# SYSCTRL register map
Registers are 32-bit, access not given, no defined reset value unless marked. A register's access mark holds for its fields unless they carry their own. Addresses are absolute; registers are grouped by the start of their names; [hi:lo] are bit positions; {n}, {i} and the like mark numbered series; 'fields as' and 'values as' point back to an identical list.

## PWRCTRL
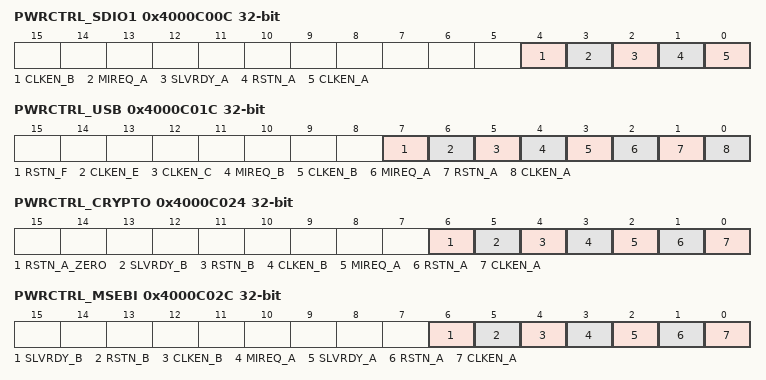
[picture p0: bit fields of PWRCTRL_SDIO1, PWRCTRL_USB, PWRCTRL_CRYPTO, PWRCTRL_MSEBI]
0x4000C00C PWRCTRL_SDIO1
  [4] CLKEN_B, [3] MIREQ_A, [2] SLVRDY_A, [1] RSTN_A, [0] CLKEN_A
0x4000C01C PWRCTRL_USB
  [7] RSTN_F, [6] CLKEN_E, [5] CLKEN_C, [4] MIREQ_B, [3] CLKEN_B, [2] MIREQ_A, [1] RSTN_A, [0] CLKEN_A
0x4000C024 PWRCTRL_CRYPTO
  [6] RSTN_A_ZERO, [5] SLVRDY_B, [4] RSTN_B, [3] CLKEN_B, [2] MIREQ_A, [1] RSTN_A, [0] CLKEN_A
0x4000C02C PWRCTRL_MSEBI
  [6] SLVRDY_B, [5] RSTN_B, [4] CLKEN_B, [3] MIREQ_A, [2] SLVRDY_A, [1] RSTN_A, [0] CLKEN_A
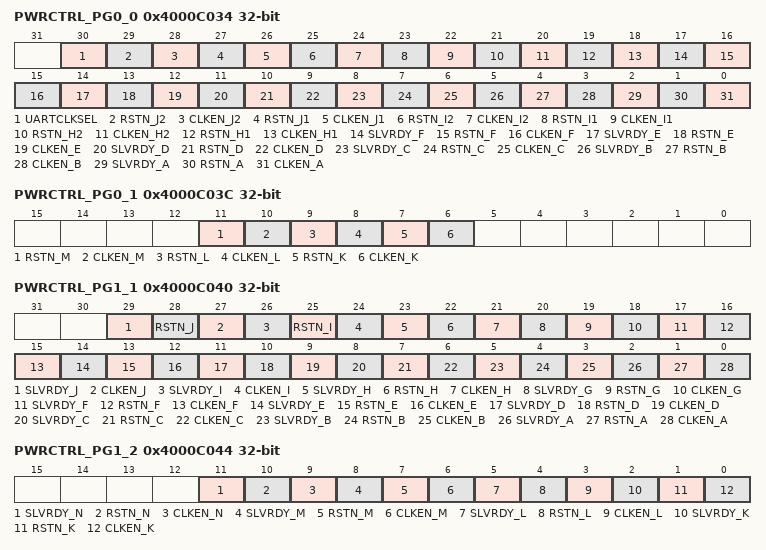
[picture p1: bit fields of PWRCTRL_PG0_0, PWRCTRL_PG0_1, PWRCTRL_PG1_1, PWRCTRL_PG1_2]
0x4000C034 PWRCTRL_PG0_0
  [30] UARTCLKSEL, [29] RSTN_J2, [28] CLKEN_J2, [27] RSTN_J1, [26] CLKEN_J1, [25] RSTN_I2, [24] CLKEN_I2, [23] RSTN_I1, [22] CLKEN_I1, [21] RSTN_H2, [20] CLKEN_H2, [19] RSTN_H1, [18] CLKEN_H1, [17] SLVRDY_F, [16] RSTN_F, [15] CLKEN_F, [14] SLVRDY_E, [13] RSTN_E, [12] CLKEN_E, [11] SLVRDY_D, [10] RSTN_D, [9] CLKEN_D, [8] SLVRDY_C, [7] RSTN_C, [6] CLKEN_C, [5] SLVRDY_B, [4] RSTN_B, [3] CLKEN_B, [2] SLVRDY_A, [1] RSTN_A, [0] CLKEN_A
0x4000C03C PWRCTRL_PG0_1
  [11] RSTN_M, [10] CLKEN_M, [9] RSTN_L, [8] CLKEN_L, [7] RSTN_K, [6] CLKEN_K
0x4000C040 PWRCTRL_PG1_1
  [29] SLVRDY_J, [28] RSTN_J, [27] CLKEN_J, [26] SLVRDY_I, [25] RSTN_I, [24] CLKEN_I, [23] SLVRDY_H, [22] RSTN_H, [21] CLKEN_H, [20] SLVRDY_G, [19] RSTN_G, [18] CLKEN_G, [17] SLVRDY_F, [16] RSTN_F, [15] CLKEN_F, [14] SLVRDY_E, [13] RSTN_E, [12] CLKEN_E, [11] SLVRDY_D, [10] RSTN_D, [9] CLKEN_D, [8] SLVRDY_C, [7] RSTN_C, [6] CLKEN_C, [5] SLVRDY_B, [4] RSTN_B, [3] CLKEN_B, [2] SLVRDY_A, [1] RSTN_A, [0] CLKEN_A
0x4000C044 PWRCTRL_PG1_2
  [11] SLVRDY_N, [10] RSTN_N, [9] CLKEN_N, [8] SLVRDY_M, [7] RSTN_M, [6] CLKEN_M, [5] SLVRDY_L, [4] RSTN_L, [3] CLKEN_L, [2] SLVRDY_K, [1] RSTN_K, [0] CLKEN_K
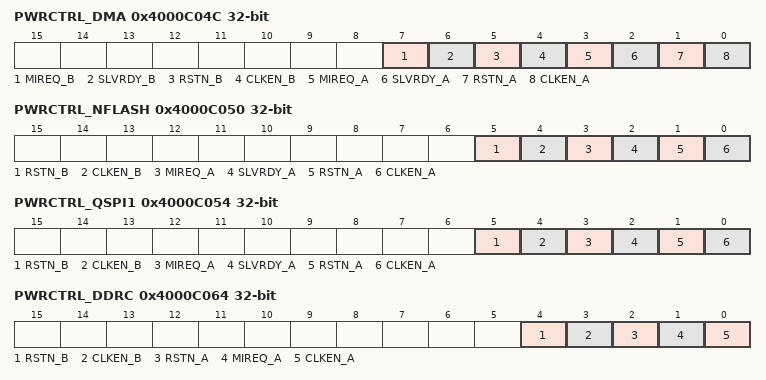
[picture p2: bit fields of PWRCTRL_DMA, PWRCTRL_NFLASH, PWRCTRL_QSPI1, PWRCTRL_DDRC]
0x4000C04C PWRCTRL_DMA
  [7] MIREQ_B, [6] SLVRDY_B, [5] RSTN_B, [4] CLKEN_B, [3] MIREQ_A, [2] SLVRDY_A, [1] RSTN_A, [0] CLKEN_A
0x4000C050 PWRCTRL_NFLASH
  [5] RSTN_B, [4] CLKEN_B, [3] MIREQ_A, [2] SLVRDY_A, [1] RSTN_A, [0] CLKEN_A
0x4000C054 PWRCTRL_QSPI1
  fields as PWRCTRL_NFLASH
0x4000C064 PWRCTRL_DDRC
  [4] RSTN_B, [3] CLKEN_B, [2] RSTN_A, [1] MIREQ_A, [0] CLKEN_A
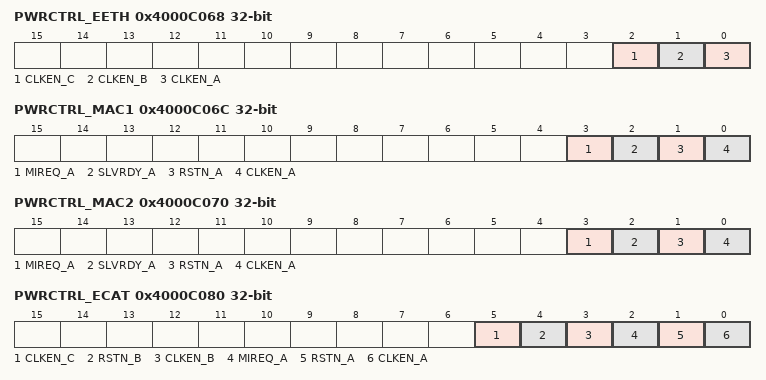
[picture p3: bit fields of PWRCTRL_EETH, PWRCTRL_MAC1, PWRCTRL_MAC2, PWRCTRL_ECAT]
0x4000C068 PWRCTRL_EETH
  [2] CLKEN_C, [1] CLKEN_B, [0] CLKEN_A
0x4000C06C PWRCTRL_MAC1
  [3] MIREQ_A, [2] SLVRDY_A, [1] RSTN_A, [0] CLKEN_A
0x4000C070 PWRCTRL_MAC2
  [3] MIREQ_A, [2] SLVRDY_A, [1] RSTN_A, [0] CLKEN_A
0x4000C080 PWRCTRL_ECAT
  [5] CLKEN_C, [4] RSTN_B, [3] CLKEN_B, [2] MIREQ_A, [1] RSTN_A, [0] CLKEN_A
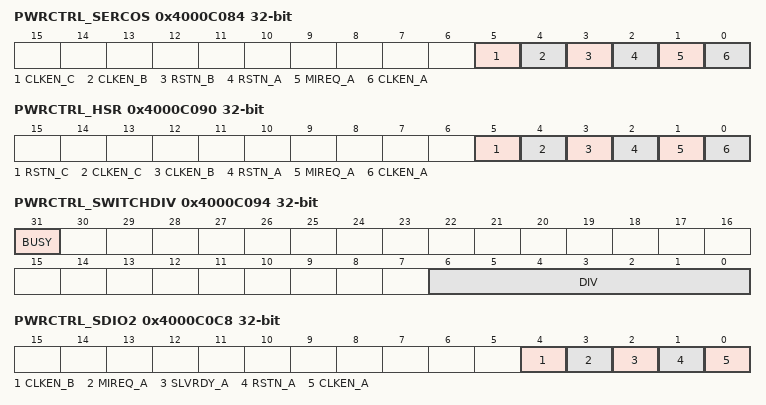
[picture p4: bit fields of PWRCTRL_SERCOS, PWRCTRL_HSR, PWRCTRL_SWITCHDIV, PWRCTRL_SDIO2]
0x4000C084 PWRCTRL_SERCOS
  [5] CLKEN_C, [4] CLKEN_B, [3] RSTN_B, [2] RSTN_A, [1] MIREQ_A, [0] CLKEN_A
0x4000C090 PWRCTRL_HSR
  [5] RSTN_C, [4] CLKEN_C, [3] CLKEN_B, [2] RSTN_A, [1] MIREQ_A, [0] CLKEN_A
0x4000C094 PWRCTRL_SWITCHDIV
  [31] BUSY, [6:0] DIV
0x4000C0C8 PWRCTRL_SDIO2
  [4] CLKEN_B, [3] MIREQ_A, [2] SLVRDY_A, [1] RSTN_A, [0] CLKEN_A
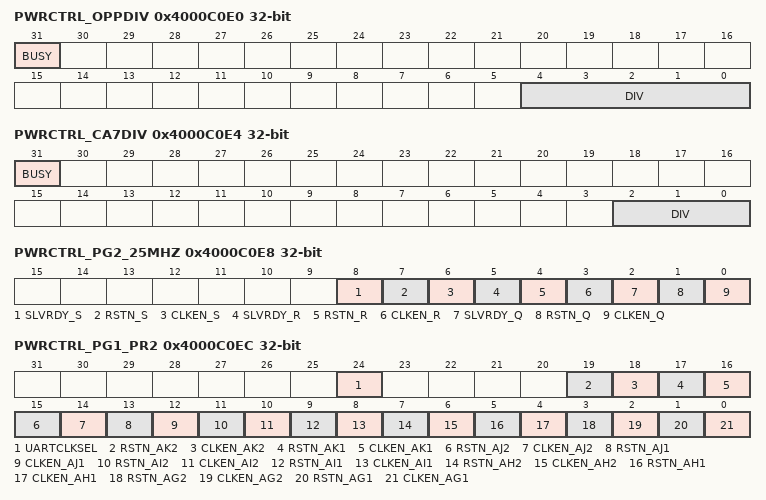
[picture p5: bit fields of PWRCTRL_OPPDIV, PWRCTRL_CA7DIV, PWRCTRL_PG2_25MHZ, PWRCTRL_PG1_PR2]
0x4000C0E0 PWRCTRL_OPPDIV
  [31] BUSY, [4:0] DIV
0x4000C0E4 PWRCTRL_CA7DIV
  [31] BUSY, [2:0] DIV
0x4000C0E8 PWRCTRL_PG2_25MHZ
  [8] SLVRDY_S, [7] RSTN_S, [6] CLKEN_S, [5] SLVRDY_R, [4] RSTN_R, [3] CLKEN_R, [2] SLVRDY_Q, [1] RSTN_Q, [0] CLKEN_Q
0x4000C0EC PWRCTRL_PG1_PR2
  [24] UARTCLKSEL, [19] RSTN_AK2, [18] CLKEN_AK2, [17] RSTN_AK1, [16] CLKEN_AK1, [15] RSTN_AJ2, [14] CLKEN_AJ2, [13] RSTN_AJ1, [12] CLKEN_AJ1, [11] RSTN_AI2, [10] CLKEN_AI2, [9] RSTN_AI1, [8] CLKEN_AI1, [7] RSTN_AH2, [6] CLKEN_AH2, [5] RSTN_AH1, [4] CLKEN_AH1, [3] RSTN_AG2, [2] CLKEN_AG2, [1] RSTN_AG1, [0] CLKEN_AG1
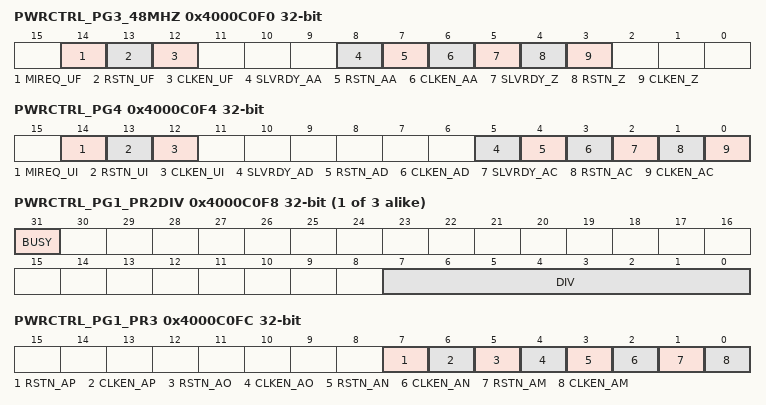
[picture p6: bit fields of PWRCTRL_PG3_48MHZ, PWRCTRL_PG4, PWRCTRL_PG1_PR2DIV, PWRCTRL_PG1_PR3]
0x4000C0F0 PWRCTRL_PG3_48MHZ
  [14] MIREQ_UF, [13] RSTN_UF, [12] CLKEN_UF, [8] SLVRDY_AA, [7] RSTN_AA, [6] CLKEN_AA, [5] SLVRDY_Z, [4] RSTN_Z, [3] CLKEN_Z
0x4000C0F4 PWRCTRL_PG4
  [14] MIREQ_UI, [13] RSTN_UI, [12] CLKEN_UI, [5] SLVRDY_AD, [4] RSTN_AD, [3] CLKEN_AD, [2] SLVRDY_AC, [1] RSTN_AC, [0] CLKEN_AC
{0x4000C0E8+8i} PWRCTRL_PG1_PR{i}DIV (i=2..4)
  [31] BUSY, [7:0] DIV
0x4000C0FC PWRCTRL_PG1_PR3
  [7] RSTN_AP, [6] CLKEN_AP, [5] RSTN_AO, [4] CLKEN_AO, [3] RSTN_AN, [2] CLKEN_AN, [1] RSTN_AM, [0] CLKEN_AM
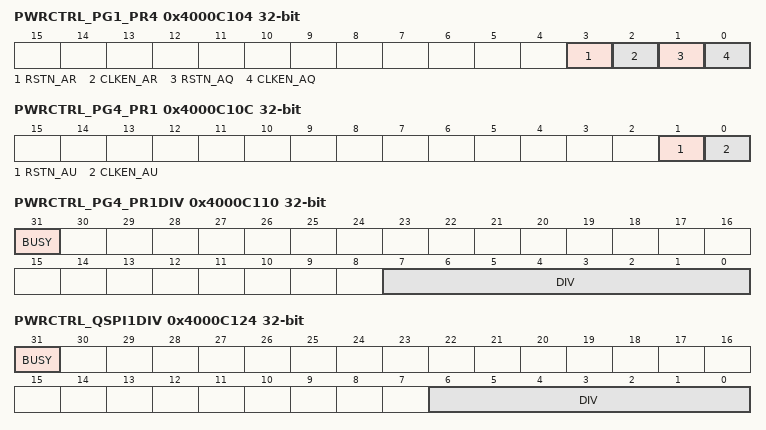
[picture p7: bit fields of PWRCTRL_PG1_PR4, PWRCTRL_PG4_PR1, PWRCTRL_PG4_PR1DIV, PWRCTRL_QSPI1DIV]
0x4000C104 PWRCTRL_PG1_PR4
  [3] RSTN_AR, [2] CLKEN_AR, [1] RSTN_AQ, [0] CLKEN_AQ
0x4000C10C PWRCTRL_PG4_PR1
  [1] RSTN_AU, [0] CLKEN_AU
0x4000C110 PWRCTRL_PG4_PR1DIV
  [31] BUSY, [7:0] DIV
0x4000C124 PWRCTRL_QSPI1DIV
  [31] BUSY, [6:0] DIV
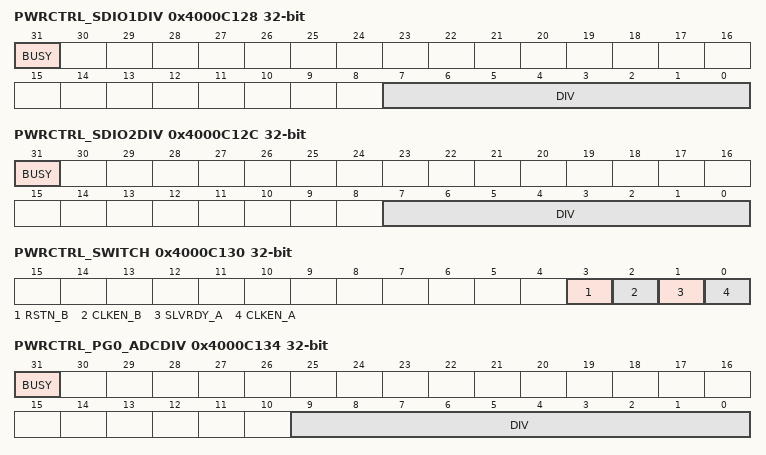
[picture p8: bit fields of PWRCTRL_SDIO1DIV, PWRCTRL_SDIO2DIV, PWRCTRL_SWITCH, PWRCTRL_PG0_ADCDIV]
0x4000C128 PWRCTRL_SDIO1DIV
  [31] BUSY, [7:0] DIV
0x4000C12C PWRCTRL_SDIO2DIV
  [31] BUSY, [7:0] DIV
0x4000C130 PWRCTRL_SWITCH
  [3] RSTN_B, [2] CLKEN_B, [1] SLVRDY_A, [0] CLKEN_A
0x4000C134 PWRCTRL_PG0_ADCDIV
  [31] BUSY, [9:0] DIV
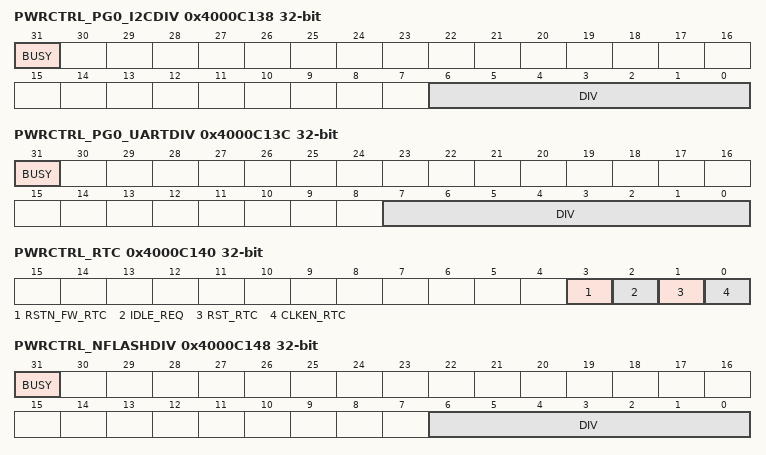
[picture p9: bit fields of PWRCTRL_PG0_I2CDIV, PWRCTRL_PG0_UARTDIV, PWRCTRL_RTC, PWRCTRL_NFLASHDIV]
0x4000C138 PWRCTRL_PG0_I2CDIV
  [31] BUSY, [6:0] DIV
0x4000C13C PWRCTRL_PG0_UARTDIV
  [31] BUSY, [7:0] DIV
0x4000C140 PWRCTRL_RTC
  [3] RSTN_FW_RTC, [2] IDLE_REQ, [1] RST_RTC, [0] CLKEN_RTC
0x4000C148 PWRCTRL_NFLASHDIV
  [31] BUSY, [6:0] DIV
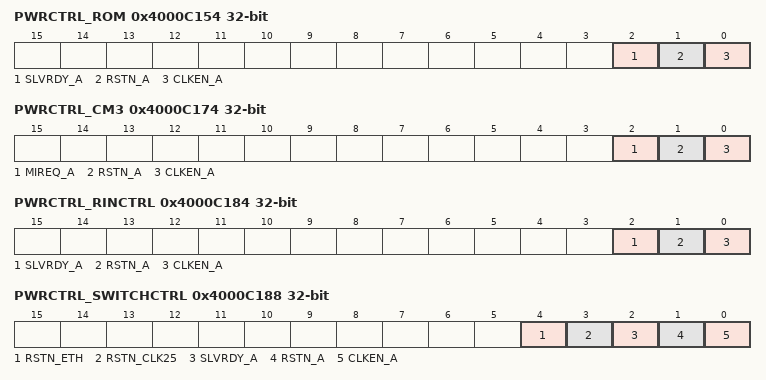
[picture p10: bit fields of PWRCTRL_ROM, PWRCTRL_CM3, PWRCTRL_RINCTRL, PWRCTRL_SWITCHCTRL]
0x4000C154 PWRCTRL_ROM
  [2] SLVRDY_A, [1] RSTN_A, [0] CLKEN_A
0x4000C174 PWRCTRL_CM3
  [2] MIREQ_A, [1] RSTN_A, [0] CLKEN_A
0x4000C184 PWRCTRL_RINCTRL
  [2] SLVRDY_A, [1] RSTN_A, [0] CLKEN_A
0x4000C188 PWRCTRL_SWITCHCTRL
  [4] RSTN_ETH, [3] RSTN_CLK25, [2] SLVRDY_A, [1] RSTN_A, [0] CLKEN_A
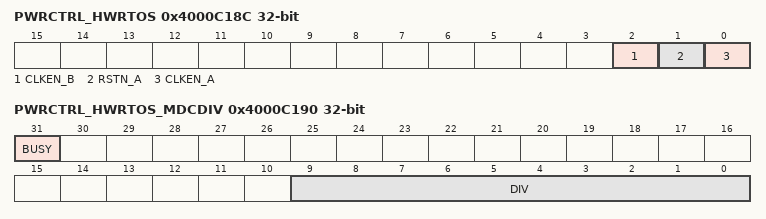
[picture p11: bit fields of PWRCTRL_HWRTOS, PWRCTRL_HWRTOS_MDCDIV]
0x4000C18C PWRCTRL_HWRTOS
  [2] CLKEN_B, [1] RSTN_A, [0] CLKEN_A
0x4000C190 PWRCTRL_HWRTOS_MDCDIV
  [31] BUSY, [9:0] DIV
